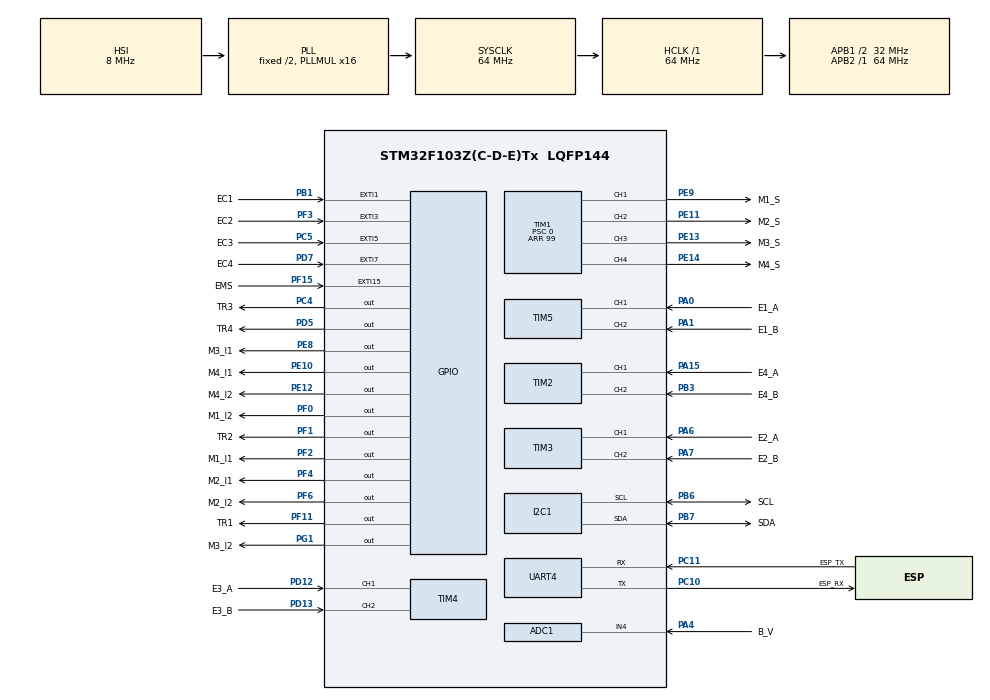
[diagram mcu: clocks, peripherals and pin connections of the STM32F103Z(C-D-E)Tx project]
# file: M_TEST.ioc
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ADC1.Channel-1\#ChannelRegularConversion=ADC_CHANNEL_4
ADC1.NbrOfConversionFlag=1
ADC1.Rank-1\#ChannelRegularConversion=1
ADC1.SamplingTime-1\#ChannelRegularConversion=ADC_SAMPLETIME_1CYCLE_5
ADC1.master=1
FREERTOS.Tasks01=defaultTask,0,128,StartDefaultTask,Default,NULL,Dynamic,NULL,NULL
Mcu.Family=STM32F1
Mcu.Name=STM32F103Z(C-D-E)Tx
Mcu.Package=LQFP144
NVIC.PriorityGroup=NVIC_PRIORITYGROUP_4
NVIC.TIM6_IRQn=true\:15\:0\:false\:false\:true\:false\:false\:true\:true
NVIC.TimeBase=TIM6_IRQn
NVIC.TimeBaseIP=TIM6
NVIC.UART4_IRQn=true\:5\:0\:false\:false\:true\:true\:true\:true\:true
PA0-WKUP.GPIO_Label=E1_A
PA0-WKUP.Signal=S_TIM5_CH1
PA1.GPIO_Label=E1_B
PA1.Signal=S_TIM5_CH2
PA15.GPIO_Label=E4_A
PA15.Signal=S_TIM2_CH1_ETR
PA4.GPIO_Label=B_V
PA4.Signal=ADCx_IN4
PA6.GPIO_Label=E2_A
PA6.Signal=S_TIM3_CH1
PA7.GPIO_Label=E2_B
PA7.Signal=S_TIM3_CH2
PB1.GPIO_Label=EC1
PB1.GPIO_ModeDefaultEXTI=GPIO_MODE_IT_RISING_FALLING
PB1.GPIO_PuPd=GPIO_PULLDOWN
PB1.Signal=GPXTI1
PB3.GPIO_Label=E4_B
PB3.Signal=S_TIM2_CH2
PB6.GPIO_Label=SCL
PB6.Mode=I2C
PB6.Signal=I2C1_SCL
PB7.GPIO_Label=SDA
PB7.Mode=I2C
PB7.Signal=I2C1_SDA
PC10.GPIO_Label=ESP_RX
PC10.Mode=Asynchronous
PC10.Signal=UART4_TX
PC11.GPIO_Label=ESP_TX
PC11.Mode=Asynchronous
PC11.Signal=UART4_RX
PC4.GPIO_Label=TR3
PC4.GPIO_Speed=GPIO_SPEED_FREQ_HIGH
PC4.Signal=GPIO_Output
PC5.GPIO_Label=EC3
PC5.GPIO_ModeDefaultEXTI=GPIO_MODE_IT_RISING_FALLING
PC5.GPIO_PuPd=GPIO_PULLDOWN
PC5.Signal=GPXTI5
PD12.GPIO_Label=E3_A
PD12.Signal=S_TIM4_CH1
PD13.GPIO_Label=E3_B
PD13.Signal=S_TIM4_CH2
PD5.GPIO_Label=TR4
PD5.GPIO_Speed=GPIO_SPEED_FREQ_HIGH
PD5.Signal=GPIO_Output
PD7.GPIO_Label=EC4
PD7.GPIO_ModeDefaultEXTI=GPIO_MODE_IT_RISING_FALLING
PD7.GPIO_PuPd=GPIO_PULLDOWN
PD7.Signal=GPXTI7
PE10.GPIO_Label=M4_I1
PE10.Signal=GPIO_Output
PE11.GPIO_Label=M2_S
PE11.Signal=S_TIM1_CH2
PE12.GPIO_Label=M4_I2
PE12.Signal=GPIO_Output
PE13.GPIO_Label=M3_S
PE13.Signal=S_TIM1_CH3
PE14.GPIO_Label=M4_S
PE14.Signal=S_TIM1_CH4
PE8.GPIO_Label=M3_I1
PE8.Signal=GPIO_Output
PE9.GPIO_Label=M1_S
PE9.Signal=S_TIM1_CH1
PF0.GPIO_Label=M1_I2
PF0.Signal=GPIO_Output
PF1.GPIO_Label=TR2
PF1.GPIO_Speed=GPIO_SPEED_FREQ_HIGH
PF1.Signal=GPIO_Output
PF11.GPIO_Label=TR1
PF11.GPIO_Speed=GPIO_SPEED_FREQ_HIGH
PF11.Signal=GPIO_Output
PF15.GPIO_Label=EMS
PF15.GPIO_ModeDefaultEXTI=GPIO_MODE_IT_RISING_FALLING
PF15.GPIO_PuPd=GPIO_PULLDOWN
PF15.Signal=GPXTI15
PF2.GPIO_Label=M1_I1
PF2.Signal=GPIO_Output
PF3.GPIO_Label=EC2
PF3.GPIO_ModeDefaultEXTI=GPIO_MODE_IT_RISING_FALLING
PF3.GPIO_PuPd=GPIO_PULLDOWN
PF3.Signal=GPXTI3
PF4.GPIO_Label=M2_I1
PF4.Signal=GPIO_Output
PF6.GPIO_Label=M2_I2
PF6.Signal=GPIO_Output
PG1.GPIO_Label=M3_I2
PG1.Signal=GPIO_Output
ProjectManager.HeapSize=0x200
ProjectManager.StackSize=0x400
ProjectManager.TargetToolchain=MDK-ARM V5.32
RCC.ADCPresc=RCC_ADCPCLK2_DIV6
RCC.AHBFreq_Value=64000000
RCC.APB1CLKDivider=RCC_HCLK_DIV2
RCC.APB1Freq_Value=32000000
RCC.APB1TimFreq_Value=64000000
RCC.APB2Freq_Value=64000000
RCC.APB2TimFreq_Value=64000000
RCC.HCLKFreq_Value=64000000
RCC.PLLMUL=RCC_PLL_MUL16
RCC.SYSCLKFreq_VALUE=64000000
RCC.SYSCLKSource=RCC_SYSCLKSOURCE_PLLCLK
RCC.USBFreq_Value=64000000
SH.ADCx_IN4.0=ADC1_IN4,IN4
SH.S_TIM1_CH1.0=TIM1_CH1,PWM Generation1 CH1
SH.S_TIM1_CH2.0=TIM1_CH2,PWM Generation2 CH2
SH.S_TIM1_CH3.0=TIM1_CH3,PWM Generation3 CH3
SH.S_TIM1_CH4.0=TIM1_CH4,PWM Generation4 CH4
SH.S_TIM2_CH1_ETR.0=TIM2_CH1,Encoder_Interface
SH.S_TIM2_CH2.0=TIM2_CH2,Encoder_Interface
SH.S_TIM3_CH1.0=TIM3_CH1,Encoder_Interface
SH.S_TIM3_CH2.0=TIM3_CH2,Encoder_Interface
SH.S_TIM4_CH1.0=TIM4_CH1,Encoder_Interface
SH.S_TIM4_CH2.0=TIM4_CH2,Encoder_Interface
SH.S_TIM5_CH1.0=TIM5_CH1,Encoder_Interface
SH.S_TIM5_CH2.0=TIM5_CH2,Encoder_Interface
TIM1.Channel-PWM\ Generation1\ CH1=TIM_CHANNEL_1
TIM1.Channel-PWM\ Generation2\ CH2=TIM_CHANNEL_2
TIM1.Channel-PWM\ Generation3\ CH3=TIM_CHANNEL_3
TIM1.Channel-PWM\ Generation4\ CH4=TIM_CHANNEL_4
TIM1.Period=99
TIM1.Prescaler=0
UART4.VirtualMode=Asynchronous
VP_FREERTOS_VS_CMSIS_V1.Mode=CMSIS_V1
VP_SYS_VS_ND.Mode=No_Debug
VP_SYS_VS_tim6.Mode=TIM6
board=custom

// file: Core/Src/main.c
/* USER CODE BEGIN Header */
/**
  ******************************************************************************
  * @file           : main.c
  * @brief          : Main program body
  ******************************************************************************
  * @attention
  *
  * Copyright (c) 2026 STMicroelectronics.
  * All rights reserved.
  *
  * This software is licensed under terms that can be found in the LICENSE file
  * in the root directory of this software component.
  * If no LICENSE file comes with this software, it is provided AS-IS.
  *
  ******************************************************************************
  */
/* USER CODE END Header */
#include "main.h"
#include "cmsis_os.h"

/* USER CODE BEGIN Includes */
#include "motor.h"
/* USER CODE END Includes */

ADC_HandleTypeDef hadc1;

I2C_HandleTypeDef hi2c1;

TIM_HandleTypeDef htim1;
TIM_HandleTypeDef htim2;
TIM_HandleTypeDef htim3;
TIM_HandleTypeDef htim4;
TIM_HandleTypeDef htim5;

UART_HandleTypeDef huart4;

osThreadId defaultTaskHandle;
/* USER CODE BEGIN PV */
uint8_t uart4_rx_char;
osMessageQId uartQueueHandle;
/* USER CODE END PV */

void SystemClock_Config(void);
static void MX_GPIO_Init(void);
static void MX_ADC1_Init(void);
static void MX_I2C1_Init(void);
static void MX_TIM2_Init(void);
static void MX_TIM3_Init(void);
static void MX_TIM4_Init(void);
static void MX_TIM5_Init(void);
static void MX_UART4_Init(void);
static void MX_TIM1_Init(void);
void StartDefaultTask(void const * argument);

int main(void)
{

  /* MCU Configuration--------------------------------------------------------*/

  /* Reset of all peripherals, Initializes the Flash interface and the Systick. */
  HAL_Init();

  /* Configure the system clock */
  SystemClock_Config();

  /* Initialize all configured peripherals */
  MX_GPIO_Init();
  MX_ADC1_Init();
  MX_I2C1_Init();
  MX_TIM2_Init();
  MX_TIM3_Init();
  MX_TIM4_Init();
  MX_TIM5_Init();
  MX_UART4_Init();
  MX_TIM1_Init();
  /* USER CODE BEGIN 2 */
	Motor_Init();
  /* USER CODE END 2 */

  /* Create the thread(s) */
  /* definition and creation of defaultTask */
  osThreadDef(defaultTask, StartDefaultTask, osPriorityNormal, 0, 128);
  defaultTaskHandle = osThreadCreate(osThread(defaultTask), NULL);

  /* USER CODE BEGIN RTOS_THREADS */
  osMessageQDef(uartQueue, 16, uint8_t);
	uartQueueHandle = osMessageCreate(osMessageQ(uartQueue), NULL);
	HAL_UART_Receive_IT(&huart4, &uart4_rx_char, 1);
  /* USER CODE END RTOS_THREADS */

  /* Start scheduler */
  osKernelStart();

  /* We should never get here as control is now taken by the scheduler */
  /* Infinite loop */
  while (1)
  {

  }
}

void SystemClock_Config(void)
{
  RCC_OscInitTypeDef RCC_OscInitStruct = {0};
  RCC_ClkInitTypeDef RCC_ClkInitStruct = {0};

  /* 用 HSI + PLL */
  RCC_OscInitStruct.OscillatorType = RCC_OSCILLATORTYPE_HSI;
  RCC_OscInitStruct.HSIState = RCC_HSI_ON;
  RCC_OscInitStruct.HSICalibrationValue = RCC_HSICALIBRATION_DEFAULT;
  RCC_OscInitStruct.PLL.PLLState = RCC_PLL_ON;
  RCC_OscInitStruct.PLL.PLLSource = RCC_PLLSOURCE_HSI_DIV2;
  RCC_OscInitStruct.PLL.PLLMUL = RCC_PLL_MUL16;

  if (HAL_RCC_OscConfig(&RCC_OscInitStruct) != HAL_OK)
  {
    Error_Handler();
  }

  /* SYSCLK = 64MHz */
  RCC_ClkInitStruct.ClockType = RCC_CLOCKTYPE_HCLK | RCC_CLOCKTYPE_SYSCLK
                              | RCC_CLOCKTYPE_PCLK1 | RCC_CLOCKTYPE_PCLK2;
  RCC_ClkInitStruct.SYSCLKSource = RCC_SYSCLKSOURCE_PLLCLK;
  RCC_ClkInitStruct.AHBCLKDivider = RCC_SYSCLK_DIV1;
  RCC_ClkInitStruct.APB1CLKDivider = RCC_HCLK_DIV2;   // 32MHz
  RCC_ClkInitStruct.APB2CLKDivider = RCC_HCLK_DIV1;   // 64MHz

  if (HAL_RCC_ClockConfig(&RCC_ClkInitStruct, FLASH_LATENCY_2) != HAL_OK)
  {
    Error_Handler();
  }
}

static void MX_ADC1_Init(void)
{

  ADC_ChannelConfTypeDef sConfig = {0};

  /** Common config
  */
  hadc1.Instance = ADC1;
  hadc1.Init.ScanConvMode = ADC_SCAN_DISABLE;
  hadc1.Init.ContinuousConvMode = DISABLE;
  hadc1.Init.DiscontinuousConvMode = DISABLE;
  hadc1.Init.ExternalTrigConv = ADC_SOFTWARE_START;
  hadc1.Init.DataAlign = ADC_DATAALIGN_RIGHT;
  hadc1.Init.NbrOfConversion = 1;
  if (HAL_ADC_Init(&hadc1) != HAL_OK)
  {
    Error_Handler();
  }

  /** Configure Regular Channel
  */
  sConfig.Channel = ADC_CHANNEL_4;
  sConfig.Rank = ADC_REGULAR_RANK_1;
  sConfig.SamplingTime = ADC_SAMPLETIME_1CYCLE_5;
  if (HAL_ADC_ConfigChannel(&hadc1, &sConfig) != HAL_OK)
  {
    Error_Handler();
  }

}

static void MX_I2C1_Init(void)
{

  hi2c1.Instance = I2C1;
  hi2c1.Init.ClockSpeed = 100000;
  hi2c1.Init.DutyCycle = I2C_DUTYCYCLE_2;
  hi2c1.Init.OwnAddress1 = 0;
  hi2c1.Init.AddressingMode = I2C_ADDRESSINGMODE_7BIT;
  hi2c1.Init.DualAddressMode = I2C_DUALADDRESS_DISABLE;
  hi2c1.Init.OwnAddress2 = 0;
  hi2c1.Init.GeneralCallMode = I2C_GENERALCALL_DISABLE;
  hi2c1.Init.NoStretchMode = I2C_NOSTRETCH_DISABLE;
  if (HAL_I2C_Init(&hi2c1) != HAL_OK)
  {
    Error_Handler();
  }

}

static void MX_TIM1_Init(void)
{

  TIM_MasterConfigTypeDef sMasterConfig = {0};
  TIM_OC_InitTypeDef sConfigOC = {0};
  TIM_BreakDeadTimeConfigTypeDef sBreakDeadTimeConfig = {0};

  htim1.Instance = TIM1;
  htim1.Init.Prescaler = 0;
  htim1.Init.CounterMode = TIM_COUNTERMODE_UP;
  htim1.Init.Period = 7199;
  htim1.Init.ClockDivision = TIM_CLOCKDIVISION_DIV1;
  htim1.Init.RepetitionCounter = 0;
  htim1.Init.AutoReloadPreload = TIM_AUTORELOAD_PRELOAD_DISABLE;
  if (HAL_TIM_PWM_Init(&htim1) != HAL_OK)
  {
    Error_Handler();
  }
  sMasterConfig.MasterOutputTrigger = TIM_TRGO_RESET;
  sMasterConfig.MasterSlaveMode = TIM_MASTERSLAVEMODE_DISABLE;
  if (HAL_TIMEx_MasterConfigSynchronization(&htim1, &sMasterConfig) != HAL_OK)
  {
    Error_Handler();
  }
  sConfigOC.OCMode = TIM_OCMODE_PWM1;
  sConfigOC.Pulse = 0;
  sConfigOC.OCPolarity = TIM_OCPOLARITY_HIGH;
  sConfigOC.OCNPolarity = TIM_OCNPOLARITY_HIGH;
  sConfigOC.OCFastMode = TIM_OCFAST_DISABLE;
  sConfigOC.OCIdleState = TIM_OCIDLESTATE_RESET;
  sConfigOC.OCNIdleState = TIM_OCNIDLESTATE_RESET;
  if (HAL_TIM_PWM_ConfigChannel(&htim1, &sConfigOC, TIM_CHANNEL_1) != HAL_OK)
  {
    Error_Handler();
  }
  if (HAL_TIM_PWM_ConfigChannel(&htim1, &sConfigOC, TIM_CHANNEL_2) != HAL_OK)
  {
    Error_Handler();
  }
  if (HAL_TIM_PWM_ConfigChannel(&htim1, &sConfigOC, TIM_CHANNEL_3) != HAL_OK)
  {
    Error_Handler();
  }
  if (HAL_TIM_PWM_ConfigChannel(&htim1, &sConfigOC, TIM_CHANNEL_4) != HAL_OK)
  {
    Error_Handler();
  }
  sBreakDeadTimeConfig.OffStateRunMode = TIM_OSSR_DISABLE;
  sBreakDeadTimeConfig.OffStateIDLEMode = TIM_OSSI_DISABLE;
  sBreakDeadTimeConfig.LockLevel = TIM_LOCKLEVEL_OFF;
  sBreakDeadTimeConfig.DeadTime = 0;
  sBreakDeadTimeConfig.BreakState = TIM_BREAK_DISABLE;
  sBreakDeadTimeConfig.BreakPolarity = TIM_BREAKPOLARITY_HIGH;
  sBreakDeadTimeConfig.AutomaticOutput = TIM_AUTOMATICOUTPUT_DISABLE;
  if (HAL_TIMEx_ConfigBreakDeadTime(&htim1, &sBreakDeadTimeConfig) != HAL_OK)
  {
    Error_Handler();
  }
  HAL_TIM_MspPostInit(&htim1);

}

static void MX_TIM2_Init(void)
{

  TIM_Encoder_InitTypeDef sConfig = {0};
  TIM_MasterConfigTypeDef sMasterConfig = {0};

  htim2.Instance = TIM2;
  htim2.Init.Prescaler = 0;
  htim2.Init.CounterMode = TIM_COUNTERMODE_UP;
  htim2.Init.Period = 65535;
  htim2.Init.ClockDivision = TIM_CLOCKDIVISION_DIV1;
  htim2.Init.AutoReloadPreload = TIM_AUTORELOAD_PRELOAD_DISABLE;
  sConfig.EncoderMode = TIM_ENCODERMODE_TI1;
  sConfig.IC1Polarity = TIM_ICPOLARITY_RISING;
  sConfig.IC1Selection = TIM_ICSELECTION_DIRECTTI;
  sConfig.IC1Prescaler = TIM_ICPSC_DIV1;
  sConfig.IC1Filter = 0;
  sConfig.IC2Polarity = TIM_ICPOLARITY_RISING;
  sConfig.IC2Selection = TIM_ICSELECTION_DIRECTTI;
  sConfig.IC2Prescaler = TIM_ICPSC_DIV1;
  sConfig.IC2Filter = 0;
  if (HAL_TIM_Encoder_Init(&htim2, &sConfig) != HAL_OK)
  {
    Error_Handler();
  }
  sMasterConfig.MasterOutputTrigger = TIM_TRGO_RESET;
  sMasterConfig.MasterSlaveMode = TIM_MASTERSLAVEMODE_DISABLE;
  if (HAL_TIMEx_MasterConfigSynchronization(&htim2, &sMasterConfig) != HAL_OK)
  {
    Error_Handler();
  }

}

static void MX_TIM3_Init(void)
{

  TIM_Encoder_InitTypeDef sConfig = {0};
  TIM_MasterConfigTypeDef sMasterConfig = {0};

  htim3.Instance = TIM3;
  htim3.Init.Prescaler = 0;
  htim3.Init.CounterMode = TIM_COUNTERMODE_UP;
  htim3.Init.Period = 65535;
  htim3.Init.ClockDivision = TIM_CLOCKDIVISION_DIV1;
  htim3.Init.AutoReloadPreload = TIM_AUTORELOAD_PRELOAD_DISABLE;
  sConfig.EncoderMode = TIM_ENCODERMODE_TI1;
  sConfig.IC1Polarity = TIM_ICPOLARITY_RISING;
  sConfig.IC1Selection = TIM_ICSELECTION_DIRECTTI;
  sConfig.IC1Prescaler = TIM_ICPSC_DIV1;
  sConfig.IC1Filter = 0;
  sConfig.IC2Polarity = TIM_ICPOLARITY_RISING;
  sConfig.IC2Selection = TIM_ICSELECTION_DIRECTTI;
  sConfig.IC2Prescaler = TIM_ICPSC_DIV1;
  sConfig.IC2Filter = 0;
  if (HAL_TIM_Encoder_Init(&htim3, &sConfig) != HAL_OK)
  {
    Error_Handler();
  }
  sMasterConfig.MasterOutputTrigger = TIM_TRGO_RESET;
  sMasterConfig.MasterSlaveMode = TIM_MASTERSLAVEMODE_DISABLE;
  if (HAL_TIMEx_MasterConfigSynchronization(&htim3, &sMasterConfig) != HAL_OK)
  {
    Error_Handler();
  }

}

static void MX_TIM4_Init(void)
{

  TIM_Encoder_InitTypeDef sConfig = {0};
  TIM_MasterConfigTypeDef sMasterConfig = {0};

  htim4.Instance = TIM4;
  htim4.Init.Prescaler = 0;
  htim4.Init.CounterMode = TIM_COUNTERMODE_UP;
  htim4.Init.Period = 65535;
  htim4.Init.ClockDivision = TIM_CLOCKDIVISION_DIV1;
  htim4.Init.AutoReloadPreload = TIM_AUTORELOAD_PRELOAD_DISABLE;
  sConfig.EncoderMode = TIM_ENCODERMODE_TI1;
  sConfig.IC1Polarity = TIM_ICPOLARITY_RISING;
  sConfig.IC1Selection = TIM_ICSELECTION_DIRECTTI;
  sConfig.IC1Prescaler = TIM_ICPSC_DIV1;
  sConfig.IC1Filter = 0;
  sConfig.IC2Polarity = TIM_ICPOLARITY_RISING;
  sConfig.IC2Selection = TIM_ICSELECTION_DIRECTTI;
  sConfig.IC2Prescaler = TIM_ICPSC_DIV1;
  sConfig.IC2Filter = 0;
  if (HAL_TIM_Encoder_Init(&htim4, &sConfig) != HAL_OK)
  {
    Error_Handler();
  }
  sMasterConfig.MasterOutputTrigger = TIM_TRGO_RESET;
  sMasterConfig.MasterSlaveMode = TIM_MASTERSLAVEMODE_DISABLE;
  if (HAL_TIMEx_MasterConfigSynchronization(&htim4, &sMasterConfig) != HAL_OK)
  {
    Error_Handler();
  }

}

static void MX_TIM5_Init(void)
{

  TIM_Encoder_InitTypeDef sConfig = {0};
  TIM_MasterConfigTypeDef sMasterConfig = {0};

  htim5.Instance = TIM5;
  htim5.Init.Prescaler = 0;
  htim5.Init.CounterMode = TIM_COUNTERMODE_UP;
  htim5.Init.Period = 65535;
  htim5.Init.ClockDivision = TIM_CLOCKDIVISION_DIV1;
  htim5.Init.AutoReloadPreload = TIM_AUTORELOAD_PRELOAD_DISABLE;
  sConfig.EncoderMode = TIM_ENCODERMODE_TI1;
  sConfig.IC1Polarity = TIM_ICPOLARITY_RISING;
  sConfig.IC1Selection = TIM_ICSELECTION_DIRECTTI;
  sConfig.IC1Prescaler = TIM_ICPSC_DIV1;
  sConfig.IC1Filter = 0;
  sConfig.IC2Polarity = TIM_ICPOLARITY_RISING;
  sConfig.IC2Selection = TIM_ICSELECTION_DIRECTTI;
  sConfig.IC2Prescaler = TIM_ICPSC_DIV1;
  sConfig.IC2Filter = 0;
  if (HAL_TIM_Encoder_Init(&htim5, &sConfig) != HAL_OK)
  {
    Error_Handler();
  }
  sMasterConfig.MasterOutputTrigger = TIM_TRGO_RESET;
  sMasterConfig.MasterSlaveMode = TIM_MASTERSLAVEMODE_DISABLE;
  if (HAL_TIMEx_MasterConfigSynchronization(&htim5, &sMasterConfig) != HAL_OK)
  {
    Error_Handler();
  }

}

static void MX_UART4_Init(void)
{

  huart4.Instance = UART4;
  huart4.Init.BaudRate = 115200;
  huart4.Init.WordLength = UART_WORDLENGTH_8B;
  huart4.Init.StopBits = UART_STOPBITS_1;
  huart4.Init.Parity = UART_PARITY_NONE;
  huart4.Init.Mode = UART_MODE_TX_RX;
  huart4.Init.HwFlowCtl = UART_HWCONTROL_NONE;
  huart4.Init.OverSampling = UART_OVERSAMPLING_16;
  if (HAL_UART_Init(&huart4) != HAL_OK)
  {
    Error_Handler();
  }

}

static void MX_GPIO_Init(void)
{
  GPIO_InitTypeDef GPIO_InitStruct = {0};

  /* GPIO Ports Clock Enable */
  __HAL_RCC_GPIOF_CLK_ENABLE();
  __HAL_RCC_GPIOA_CLK_ENABLE();
  __HAL_RCC_GPIOC_CLK_ENABLE();
  __HAL_RCC_GPIOB_CLK_ENABLE();
  __HAL_RCC_GPIOG_CLK_ENABLE();
  __HAL_RCC_GPIOE_CLK_ENABLE();
  __HAL_RCC_GPIOD_CLK_ENABLE();

  /*Configure GPIO pin Output Level */
  HAL_GPIO_WritePin(GPIOF, M1_I2_Pin|TR2_Pin|M1_I1_Pin|M2_I1_Pin
                          |M2_I2_Pin|TR1_Pin, GPIO_PIN_RESET);

  /*Configure GPIO pin Output Level */
  HAL_GPIO_WritePin(TR3_GPIO_Port, TR3_Pin, GPIO_PIN_RESET);

  /*Configure GPIO pin Output Level */
  HAL_GPIO_WritePin(M3_I2_GPIO_Port, M3_I2_Pin, GPIO_PIN_RESET);

  /*Configure GPIO pin Output Level */
  HAL_GPIO_WritePin(GPIOE, M3_I1_Pin|M4_I1_Pin|M4_I2_Pin, GPIO_PIN_RESET);

  /*Configure GPIO pin Output Level */
  HAL_GPIO_WritePin(TR4_GPIO_Port, TR4_Pin, GPIO_PIN_RESET);

  /*Configure GPIO pins : M1_I2_Pin M1_I1_Pin M2_I1_Pin M2_I2_Pin */
  GPIO_InitStruct.Pin = M1_I2_Pin|M1_I1_Pin|M2_I1_Pin|M2_I2_Pin;
  GPIO_InitStruct.Mode = GPIO_MODE_OUTPUT_PP;
  GPIO_InitStruct.Pull = GPIO_NOPULL;
  GPIO_InitStruct.Speed = GPIO_SPEED_FREQ_LOW;
  HAL_GPIO_Init(GPIOF, &GPIO_InitStruct);

  /*Configure GPIO pins : TR2_Pin TR1_Pin */
  GPIO_InitStruct.Pin = TR2_Pin|TR1_Pin;
  GPIO_InitStruct.Mode = GPIO_MODE_OUTPUT_PP;
  GPIO_InitStruct.Pull = GPIO_NOPULL;
  GPIO_InitStruct.Speed = GPIO_SPEED_FREQ_HIGH;
  HAL_GPIO_Init(GPIOF, &GPIO_InitStruct);

  /*Configure GPIO pins : EC2_Pin EMS_Pin */
  GPIO_InitStruct.Pin = EC2_Pin|EMS_Pin;
  GPIO_InitStruct.Mode = GPIO_MODE_IT_RISING_FALLING;
  GPIO_InitStruct.Pull = GPIO_PULLDOWN;
  HAL_GPIO_Init(GPIOF, &GPIO_InitStruct);

  /*Configure GPIO pin : TR3_Pin */
  GPIO_InitStruct.Pin = TR3_Pin;
  GPIO_InitStruct.Mode = GPIO_MODE_OUTPUT_PP;
  GPIO_InitStruct.Pull = GPIO_NOPULL;
  GPIO_InitStruct.Speed = GPIO_SPEED_FREQ_HIGH;
  HAL_GPIO_Init(TR3_GPIO_Port, &GPIO_InitStruct);

  /*Configure GPIO pin : EC3_Pin */
  GPIO_InitStruct.Pin = EC3_Pin;
  GPIO_InitStruct.Mode = GPIO_MODE_IT_RISING_FALLING;
  GPIO_InitStruct.Pull = GPIO_PULLDOWN;
  HAL_GPIO_Init(EC3_GPIO_Port, &GPIO_InitStruct);

  /*Configure GPIO pin : EC1_Pin */
  GPIO_InitStruct.Pin = EC1_Pin;
  GPIO_InitStruct.Mode = GPIO_MODE_IT_RISING_FALLING;
  GPIO_InitStruct.Pull = GPIO_PULLDOWN;
  HAL_GPIO_Init(EC1_GPIO_Port, &GPIO_InitStruct);

  /*Configure GPIO pin : M3_I2_Pin */
  GPIO_InitStruct.Pin = M3_I2_Pin;
  GPIO_InitStruct.Mode = GPIO_MODE_OUTPUT_PP;
  GPIO_InitStruct.Pull = GPIO_NOPULL;
  GPIO_InitStruct.Speed = GPIO_SPEED_FREQ_LOW;
  HAL_GPIO_Init(M3_I2_GPIO_Port, &GPIO_InitStruct);

  /*Configure GPIO pins : M3_I1_Pin M4_I1_Pin M4_I2_Pin */
  GPIO_InitStruct.Pin = M3_I1_Pin|M4_I1_Pin|M4_I2_Pin;
  GPIO_InitStruct.Mode = GPIO_MODE_OUTPUT_PP;
  GPIO_InitStruct.Pull = GPIO_NOPULL;
  GPIO_InitStruct.Speed = GPIO_SPEED_FREQ_LOW;
  HAL_GPIO_Init(GPIOE, &GPIO_InitStruct);

  /*Configure GPIO pin : TR4_Pin */
  GPIO_InitStruct.Pin = TR4_Pin;
  GPIO_InitStruct.Mode = GPIO_MODE_OUTPUT_PP;
  GPIO_InitStruct.Pull = GPIO_NOPULL;
  GPIO_InitStruct.Speed = GPIO_SPEED_FREQ_HIGH;
  HAL_GPIO_Init(TR4_GPIO_Port, &GPIO_InitStruct);

  /*Configure GPIO pin : EC4_Pin */
  GPIO_InitStruct.Pin = EC4_Pin;
  GPIO_InitStruct.Mode = GPIO_MODE_IT_RISING_FALLING;
  GPIO_InitStruct.Pull = GPIO_PULLDOWN;
  HAL_GPIO_Init(EC4_GPIO_Port, &GPIO_InitStruct);

}

/* USER CODE BEGIN 4 */
void HAL_UART_RxCpltCallback(UART_HandleTypeDef *huart)
{
    if (huart->Instance == UART4)
    {
			  uint8_t msg[] = "OK\r\n";
        HAL_UART_Transmit(&huart4, msg, sizeof(msg) - 1, 100);

        osMessagePut(uartQueueHandle, uart4_rx_char, 0);

        HAL_UART_Receive_IT(&huart4, &uart4_rx_char, 1);
    }
}

/* USER CODE END 4 */

void StartDefaultTask(void const * argument)
{
    osEvent evt;
    uint8_t rx;

    Motor_Init();

    for(;;)
    {
        evt = osMessageGet(uartQueueHandle, osWaitForever);

        if (evt.status == osEventMessage)
        {
            rx = (uint8_t)evt.value.v;

            if (rx == '1')
            {
              Motor_Speed_Percent(1, 50, 1);
							Motor_Speed_Percent(2, 50, 1);
							Motor_Speed_Percent(3, 50, 1);
							Motor_Speed_Percent(4, 50, 1);
            }
            else if (rx == '2')
            {
              Motor_Speed_Percent(1, 50, -1);
							Motor_Speed_Percent(2, 50, -1);
							Motor_Speed_Percent(3, 50, -1);
							Motor_Speed_Percent(4, 50, -1);
            }
						else if (rx == '3')
            {
              Motor_Speed_Percent(1, 0, 0);
							Motor_Speed_Percent(2, 50, 1);
							Motor_Speed_Percent(3, 0, 0);
							Motor_Speed_Percent(4, 50, -1);
            }
						else if (rx == '4')
            {
              Motor_Speed_Percent(1, 50, 1);
							Motor_Speed_Percent(2, 0, 0);
							Motor_Speed_Percent(3, 50, -1);
							Motor_Speed_Percent(4, 0, 0);
            }
						else if (rx == '5')
            {
              Motor_Speed_Percent(1, 50, -1);
							Motor_Speed_Percent(2, 50, 1);
							Motor_Speed_Percent(3, 50, 1);
							Motor_Speed_Percent(4, 50, -1);
            }
						else if (rx == '6')
            {
              Motor_Speed_Percent(1, 50, 1);
							Motor_Speed_Percent(2, 50, -1);
							Motor_Speed_Percent(3, 50, -1);
							Motor_Speed_Percent(4, 50, 1);
            }
            else if (rx == '7')
            {
              Motor_Speed_Percent(1, 0, 0);
							Motor_Speed_Percent(2, 0, 0);
							Motor_Speed_Percent(3, 0, 0);
							Motor_Speed_Percent(4, 0, 0);
            }
        }
    }
}

void HAL_TIM_PeriodElapsedCallback(TIM_HandleTypeDef *htim)
{
  if (htim->Instance == TIM6) {
    HAL_IncTick();
  }
}

void Error_Handler(void)
{
  __disable_irq();
  while (1)
  {
  }
}
